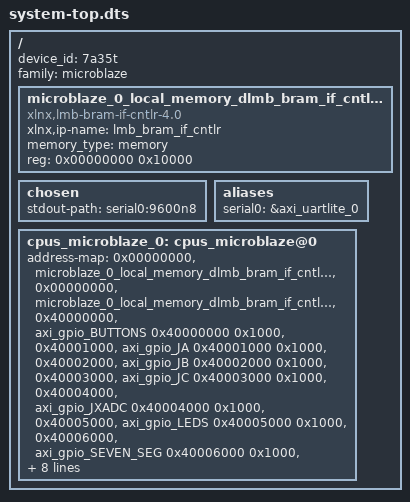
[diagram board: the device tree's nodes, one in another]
/dts-v1/;
#include "pl.dtsi"
/ {
	device_id = "7a35t";
	#address-cells = <1>;
	#size-cells = <1>;
	family = "microblaze";
	microblaze_0_local_memory_dlmb_bram_if_cntlr_memory: memory@0 {
		compatible = "xlnx,lmb-bram-if-cntlr-4.0";
		xlnx,ip-name = "lmb_bram_if_cntlr";
		device_type = "memory";
		memory_type = "memory";
		reg = <0x00000000 0x10000>;
	};
	chosen {
		stdout-path = "serial0:9600n8";
	};
	aliases {
		serial0 = &axi_uartlite_0;
	};
	cpus_microblaze_0: cpus_microblaze@0 {
		address-map = <0x00000000 &microblaze_0_local_memory_dlmb_bram_if_cntlr_memory 0x00000000 0x10000>, 
			      <0x00000000 &microblaze_0_local_memory_dlmb_bram_if_cntlr 0x00000000 0x10000>, 
			      <0x40000000 &axi_gpio_BUTTONS 0x40000000 0x1000>, 
			      <0x40001000 &axi_gpio_JA 0x40001000 0x1000>, 
			      <0x40002000 &axi_gpio_JB 0x40002000 0x1000>, 
			      <0x40003000 &axi_gpio_JC 0x40003000 0x1000>, 
			      <0x40004000 &axi_gpio_JXADC 0x40004000 0x1000>, 
			      <0x40005000 &axi_gpio_LEDS 0x40005000 0x1000>, 
			      <0x40006000 &axi_gpio_SEVEN_SEG 0x40006000 0x1000>, 
			      <0x40007000 &axi_gpio_SWITCHES 0x40007000 0x1000>, 
			      <0x40008000 &axi_uartlite_0 0x40008000 0x1000>, 
			      <0x40009000 &axi_timer_0 0x40009000 0x1000>, 
			      <0x4000a000 &axi_timer_1 0x4000a000 0x1000>, 
			      <0x4000b000 &axi_timer_2 0x4000b000 0x1000>, 
			      <0x4000c000 &axi_timer_3 0x4000c000 0x1000>;
		#ranges-address-cells = <0x1>;
		#ranges-size-cells = <0x1>;
	};
};
